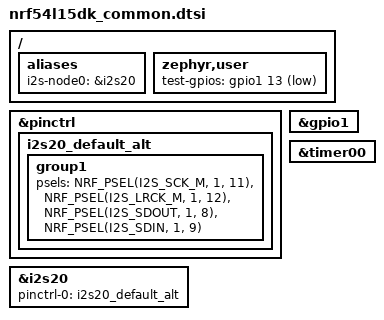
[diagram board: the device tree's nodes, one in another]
/*
 * Copyright (c) 2025 Nordic Semiconductor ASA
 *
 * SPDX-License-Identifier: LicenseRef-Nordic-5-Clause
 */

/* Test requires wire connection:
 *  - I2S_LRCK_M with test-gpios -> P1.12 - P1.13.
 */

/ {
	aliases {
		i2s-node0 = &i2s20;
	};
};

/ {
	zephyr,user {
		test-gpios = <&gpio1 13 GPIO_ACTIVE_LOW>;
	};
};

&pinctrl {
	i2s20_default_alt: i2s20_default_alt {
		group1 {
			psels = <NRF_PSEL(I2S_SCK_M, 1, 11)>,
				<NRF_PSEL(I2S_LRCK_M, 1, 12)>,
				<NRF_PSEL(I2S_SDOUT, 1, 8)>,
				<NRF_PSEL(I2S_SDIN, 1, 9)>;
		};
	};
};

&gpio1 {
	status = "okay";
};

&i2s20 {
	status = "okay";
	pinctrl-0 = <&i2s20_default_alt>;
	pinctrl-names = "default";
};

&timer00 {
	status = "okay";
};
